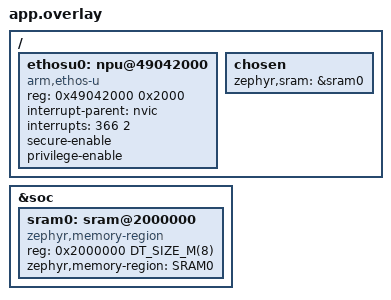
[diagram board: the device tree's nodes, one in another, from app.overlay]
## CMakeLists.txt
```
# SPDX-License-Identifier: Apache-2.0

cmake_minimum_required(VERSION 3.20.0)

# Select the AI layer's Kconfig fragments before Zephyr processes configuration.
list(APPEND EXTRA_CONF_FILE
  "${CMAKE_CURRENT_SOURCE_DIR}/ai_layer/components.conf"
  "${CMAKE_CURRENT_SOURCE_DIR}/ai_layer/operators.conf"
)

# Include the NPU node even when an older build cache has an empty overlay list.
if(NOT DTC_OVERLAY_FILE)
  set(DTC_OVERLAY_FILE "${CMAKE_CURRENT_SOURCE_DIR}/app.overlay")
endif()

find_package(Zephyr REQUIRED HINTS $ENV{ZEPHYR_BASE})
project(my_app)

add_subdirectory(ai_layer)

# Keep ExecuTorch warning suppressions local to its library.
target_compile_options(cmsis_executorch PRIVATE
  $<$<COMPILE_LANGUAGE:CXX>:-Wno-deprecated-declarations>
  $<$<COMPILE_LANG_AND_ID:CXX,GNU>:-Wno-psabi>
)

# Zephyr already provides sys/types.h for AC6; the bare-metal pack shim
# must not shadow it. Only libc++ needs compatibility adjustments here.
if(CMAKE_CXX_COMPILER_ID STREQUAL "ARMClang")
  zephyr_compile_options(-ffp-mode=full)
  # AC6 ctype macros return shifted bit masks; Zephyr's fnmatch.c uses them
  # as booleans. Put the suppression on the source so it follows -Wall;
  # a target option precedes Zephyr's flags and gets overridden by AC6.
  if(TARGET lib__posix__c_lib_ext)
    set_property(SOURCE "${ZEPHYR_BASE}/lib/posix/c_lib_ext/fnmatch.c"
      TARGET_DIRECTORY lib__posix__c_lib_ext
      APPEND PROPERTY COMPILE_OPTIONS -Wno-int-in-bool-context)
  endif()
  # Zephyr's armstdc wrappers use #include_next to chain into AC6's C headers,
  # and AC6 6.24's libc++ wrappers must precede both (notably stddef.h).
  # Explicitly add both system include paths in order: libcxx -> armstdc -> include.
  get_filename_component(_ac6_bin "${CMAKE_CXX_COMPILER}" DIRECTORY)
  get_filename_component(_ac6_include "${_ac6_bin}/../include" ABSOLUTE)
  get_filename_component(_ac6_libcxx "${_ac6_include}/libcxx" ABSOLUTE)
  if(IS_DIRECTORY "${_ac6_libcxx}")
    target_include_directories(zephyr_interface SYSTEM BEFORE INTERFACE
      "$<$<COMPILE_LANGUAGE:CXX>:${_ac6_libcxx}>")
  endif()
  if(IS_DIRECTORY "${_ac6_include}")
    target_include_directories(zephyr_interface SYSTEM INTERFACE
      "${_ac6_include}")
  endif()
  zephyr_compile_options(
    "$<$<COMPILE_LANGUAGE:CXX>:-include${CMAKE_CURRENT_SOURCE_DIR}/src/zephyr_ac6_compat.hpp>")

  # Zephyr's CMake scatter generator disables CONFIG_STATIC_INIT_GNU,
  # omitting the constructor runner and the companion destructor handler.
  if(NOT CONFIG_STATIC_INIT_GNU)
    zephyr_linker_section_configure(SECTION ctors
      INPUT ".init_array*" SORT NAME KEEP
      SYMBOLS __ac6_init_array_start __ac6_init_array_end)
    zephyr_link_libraries("--keep=*.o(.init_array*)")
    target_sources(app PRIVATE src/zephyr_ac6_init.c
      "${ZEPHYR_BASE}/lib/cpp/abi/cpp_dtors.c")
  endif()

  # Zephyr hard-codes microlib for armlink. ExecuTorch's full libc++ needs
  # the standard Arm C runtime (wide strings and AEABI assertions).
  foreach(_elf zephyr_pre0 zephyr_pre1 zephyr_final)
    if(TARGET ${_elf})
      get_target_property(_libs ${_elf} LINK_LIBRARIES)
      list(REMOVE_ITEM _libs "--library_type=microlib")
      set_property(TARGET ${_elf} PROPERTY LINK_LIBRARIES "${_libs}")
    endif()
  endforeach()
endif()

target_sources(app PRIVATE
  src/main.c
  src/arm_embedded_module.cpp
)
target_include_directories(app PRIVATE src)
if(CONFIG_EXECUTORCH_MULTIPLE_TEST)
  target_sources(app PRIVATE src/executorch_multiple_test.cpp)
else()
  target_sources(app PRIVATE src/executorch_test.cpp)
endif()

# The Corstone FVP watches UART output for EOT (0x04). Physical targets must
# not receive this control character, so enable it only from the FVP context.
if(FVP_SHUTDOWN_ON_EOT)
  target_compile_definitions(app PRIVATE FVP_SHUTDOWN_ON_EOT=1)
endif()

# Keep runtime logging consistent with the existing AI layer configuration.
zephyr_compile_definitions(ET_LOG_ENABLED=0)
```

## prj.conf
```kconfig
# The user-facing solution runs the standard single-method test.
CONFIG_EXECUTORCH_MULTIPLE_TEST=n

# Zephyr 4.5 driver configuration for the E8 NPU-HG: Ethos-U85 with 256 MACs
# per cycle. These are Zephyr Kconfig symbols, not CMSIS-Ethos-U pack settings.
CONFIG_ETHOS_U=y
CONFIG_ETHOS_U85_256=y
CONFIG_ETHOS_U_ARM=y
#CONFIG_ETHOS_U_LOG_LEVEL_NONE=y

# Ethos-U synchronization uses the kernel heap.
CONFIG_HEAP_MEM_POOL_SIZE=16384
# C++ allocations must use a heap initialized by Zephyr, including with AC6.
CONFIG_COMMON_LIBC_MALLOC=y
CONFIG_COMMON_LIBC_MALLOC_ARENA_SIZE=65536
CONFIG_LOG=y
# Keep the boot banner and kernel logs in order with the runtime's direct printf.
CONFIG_LOG_MODE_IMMEDIATE=y
CONFIG_ETHOS_U_LOG_LEVEL_INF=y
CONFIG_CACHE_MANAGEMENT=y
CONFIG_ETHOS_U_DCACHE=y

CONFIG_CPP=y
CONFIG_STD_CPP17=y

# Let Zephyr request frame-pointer omission even in unoptimized builds.
CONFIG_OVERRIDE_FRAME_POINTER_DEFAULT=y
CONFIG_OMIT_FRAME_POINTER=y

# Use the Cortex-M hardware FPU and pass floating-point arguments in FP registers.
CONFIG_FPU=y
CONFIG_FP_HARDABI=y

# Runtime loading uses C++ containers; the runner also prints float logits.
CONFIG_MAIN_STACK_SIZE=16384
CONFIG_REQUIRES_FLOAT_PRINTF=y
```

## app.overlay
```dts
/* SPDX-License-Identifier: Apache-2.0 */

/* The Ethos-U cannot DMA to the Cortex-M55 DTCM selected by the board DTS.
 * Combine SRAM0 and SRAM1 into one NPU-accessible application RAM region.
 */
/delete-node/ &sram0;
/delete-node/ &sram1;

&soc {
	sram0: sram@2000000 {
		compatible = "zephyr,memory-region", "mmio-sram";
		reg = <0x2000000 DT_SIZE_M(8)>;
		zephyr,memory-region = "SRAM0";
	};
};

/ {
	/* Alif Ensemble 2.2.1: NPU_HG_BASE and M55_HP IRQ366 (Ethos-U85). */
	ethosu0: npu@49042000 {
		compatible = "arm,ethos-u";
		reg = <0x49042000 0x2000>;
		interrupt-parent = <&nvic>;
		interrupts = <366 2>;
		secure-enable;
		privilege-enable;
		status = "okay";
	};

	chosen {
		zephyr,sram = &sram0;
	};
};
```

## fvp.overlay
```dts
/* SPDX-License-Identifier: Apache-2.0 */

/*
 * The Corstone-320 Zephyr board already declares its Ethos-U85. Keep this
 * overlay separate from app.overlay, which contains the Alif E8 NPU node.
 */

/* The SSE-320 FVP exposes UART0 in the BSP's FPGA UART window at 0x59303000.
 * The reg value is relative to the peripheral bus's 0x50000000 base.
 */
&uart0 {
	reg = <0x09303000 0x1000>;
};

/* These external UARTs use GPIO pin muxing that faults on the FVP. */
&uart3 {
	status = "disabled";
};

&uart4 {
	status = "disabled";
};

/ {
	ethosu0 {
		status = "okay";
	};
};
```

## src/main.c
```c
/*
 * Copyright (c) 2012-2014 Wind River Systems, Inc.
 *
 * SPDX-License-Identifier: Apache-2.0
 */

#include <errno.h>
#include <inttypes.h>
#include <stdio.h>

#include <zephyr/device.h>
#include <zephyr/devicetree.h>

#include <ethosu_driver.h>

#include "executorch_test.h"

#define NPU_NODE DT_NODELABEL(ethosu0)

static int finish(int result)
{
#ifdef FVP_SHUTDOWN_ON_EOT
	/* fvp_config.txt has shutdown_on_eot=1, so this ends an FVP run promptly. */
	putchar('\x04');
	fflush(stdout);
#endif
	return result;
}

int main(void)
{
	const struct device *npu = DEVICE_DT_GET(NPU_NODE);
	struct ethosu_driver_version version;
	struct ethosu_hw_info hw;
	struct ethosu_driver *drv;
	int ret = 0;

	printf("Hello World! %s\n", CONFIG_BOARD_TARGET);
	printf("Ethos-U85 (NPU-HG) driver communication check\n");
	printf("Device: %s, base: 0x%08" PRIxPTR ", IRQ: %u\n", npu->name,
	       (uintptr_t)DT_REG_ADDR(NPU_NODE), DT_IRQN(NPU_NODE));

	ethosu_get_driver_version(&version);
	printf("Driver version: %u.%u.%u\n", version.major, version.minor, version.patch);

	/* Do not reserve a driver if initialization failed: reservation would block. */
	if (!device_is_ready(npu)) {
		printf("ERROR: Ethos-U85 device initialization failed. Check the driver logs "
		       "and the board's NPU power, clock and security configuration.\n");
		return finish(-ENODEV);
	}

	drv = ethosu_reserve_driver();
	if (drv == NULL) {
		printf("ERROR: Could not reserve the Ethos-U85 driver.\n");
		return finish(-ENODEV);
	}

	/* This API reads the NPU's ID and CONFIG registers through the core driver. */
	ethosu_get_hw_info(drv, &hw);
	printf("Hardware architecture: %" PRIu32 ".%" PRIu32 ".%" PRIu32 "\n",
	       hw.version.arch_major_rev, hw.version.arch_minor_rev,
	       hw.version.arch_patch_rev);
	printf("Hardware revision: %" PRIu32 ".%" PRIu32 " (status %" PRIu32 ")\n",
	       hw.version.version_major, hw.version.version_minor, hw.version.version_status);
	printf("Product revision: %" PRIu32 "\n", hw.version.product_major);
	printf("Command stream version: %" PRIu32 "\n", hw.cfg.cmd_stream_version);
	printf("Custom DMA: %" PRIu32 "\n", hw.cfg.custom_dma);

	/* macs_per_cc is encoded as log2(MACs per cycle) by the hardware. */
	if (hw.cfg.macs_per_cc < 32U) {
		uint32_t macs = UINT32_C(1) << hw.cfg.macs_per_cc;

		printf("MACs per cycle: %" PRIu32 "\n", macs);
		if (macs != 256U) {
			printf("ERROR: Expected the E8's 256-MAC Ethos-U85 configuration.\n");
			ret = -EINVAL;
		}
	} else {
		printf("ERROR: Invalid MAC configuration: %" PRIu32 "\n", hw.cfg.macs_per_cc);
		ret = -EINVAL;
	}

	ethosu_release_driver(drv);
	if (ret == 0) {
		printf("Ethos-U85 driver communication OK (ID/configuration read; no inference).\n");
		return finish(executorch_run_test());
	}

	return finish(ret);
}
```

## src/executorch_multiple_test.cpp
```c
// Copyright 2026 Arm Limited and/or its affiliates.
// SPDX-License-Identifier: Apache-2.0

#include <array>
#include <cmath>
#include <cstdint>
#include <cstdio>
#include <cstring>
#include <limits>
#include <memory>
#include <vector>

#include <executorch/extension/data_loader/buffer_data_loader.h>
#include <executorch/runtime/core/evalue.h>
#include <executorch/runtime/core/exec_aten/exec_aten.h>
#include <executorch/runtime/core/memory_allocator.h>
#include <executorch/runtime/platform/runtime.h>

#include "arm_embedded_module.hpp"
#include "TinyCNNMultiple_pte.h"

using arm::embedded::EmbeddedModule;
using executorch::aten::DimOrderType;
using executorch::aten::ScalarType;
using executorch::aten::SizesType;
using executorch::aten::Tensor;
using executorch::aten::TensorImpl;
using executorch::extension::BufferDataLoader;
using executorch::runtime::EValue;
using executorch::runtime::MemoryAllocator;

namespace {

// Both methods stay loaded; their planned buffers have independent lifetimes.
constexpr size_t kMethodPoolSize = 256 * 1024;
constexpr size_t kTempPoolSize = 64 * 1024;

// The scratch pool must be in memory accessible to the NPU.
#ifdef APP_POOL_SECTION
#define MULTIPLE_POOL_ATTRIBUTES __attribute__((section(APP_POOL_SECTION)))
#else
#define MULTIPLE_POOL_ATTRIBUTES
#endif
alignas(64) uint8_t g_method_pool[kMethodPoolSize] MULTIPLE_POOL_ATTRIBUTES;
alignas(64) uint8_t g_temp_pool[kTempPoolSize] MULTIPLE_POOL_ATTRIBUTES;

// quantize_TinyCNNMultiple.py, seed 0, uniform input 0.25. Allow a few INT8
// rounding steps across CMSIS-NN and Ethos-U implementations.
constexpr std::array<float, 10> kReference = {
  -0.0271001998f, 0.0707616359f, 0.0542003997f, -0.0526948310f,
   0.0391447321f, 0.0271001998f, -0.0376391672f, -0.0557059646f,
  -0.1400177032f, 0.0f,
};
constexpr float kTolerance = 0.006f;

bool fail(const char *operation)
{
  printf("ExecuTorch multiple: %s failed\nTest_result: FAIL\n", operation);
  return false;
}

// Model dimensions are exported as zero-input constant methods in the .pt2.
// Reading them avoids duplicating shape constants in the application.
bool read_integer(EmbeddedModule &module, const char *name, SizesType &value)
{
  auto values = module.execute(name, std::vector<EValue>{});
  if (!values.ok() || values->size() != 1 || !values->front().isInt() ||
      values->front().toInt() <= 0 ||
      values->front().toInt() > std::numeric_limits<SizesType>::max()) {
    return fail(name);
  }
  value = static_cast<SizesType>(values->front().toInt());
  printf("%s: %ld\n", name, static_cast<long>(value));
  return true;
}

// Translate a row-major logical index into the storage layout reported by
// ExecuTorch. CPU and NPU-lowered methods may use different dimension orders.
template <class Sizes, class Strides>
size_t physical_offset(size_t logical, const Sizes &sizes, const Strides &strides)
{
  size_t offset = 0;
  for (size_t dimension = sizes.size(); dimension-- > 0;) {
    offset += (logical % sizes[dimension]) * strides[dimension];
    logical /= sizes[dimension];
  }
  return offset;
}

// Validate one named method, adapt its input layout, execute it synchronously,
// and copy the result into application-owned storage for the next stage.
template <size_t OutputRank>
bool run_method(EmbeddedModule &module, const char *method,
                const std::array<SizesType, 4> &image_shape, const std::vector<float> &input,
                const std::array<SizesType, OutputRank> &output_shape, std::vector<float> &output)
{
  auto metadata = module.method_meta(method);
  if (!metadata.ok() || metadata->num_inputs() != 1 || metadata->num_outputs() != 1) {
    return fail("method metadata");
  }
  auto tensor_metadata = metadata->input_tensor_meta(0);
  auto output_metadata = metadata->output_tensor_meta(0);
  if (!tensor_metadata.ok() || !output_metadata.ok() ||
      tensor_metadata->scalar_type() != ScalarType::Float ||
      output_metadata->scalar_type() != ScalarType::Float ||
      tensor_metadata->sizes().size() != image_shape.size() ||
      tensor_metadata->dim_order().size() != image_shape.size() ||
      output_metadata->sizes().size() != output_shape.size() ||
      tensor_metadata->nbytes() != input.size() * sizeof(float) ||
      output_metadata->nbytes() != output.size() * sizeof(float)) {
    return fail("tensor metadata");
  }
  auto sizes = image_shape;
  std::array<DimOrderType, 4> order{};
  std::array<size_t, 4> strides{};
  for (size_t i = 0; i < image_shape.size(); ++i) {
    if (tensor_metadata->sizes()[i] != image_shape[i]) {
      return fail("input shape");
    }
    order[i] = tensor_metadata->dim_order()[i];
  }
  for (size_t i = 0; i < output_shape.size(); ++i) {
    if (output_metadata->sizes()[i] != output_shape[i]) {
      return fail("output shape");
    }
  }
  size_t stride = 1;
  for (size_t i = image_shape.size(); i-- > 0;) {
    strides[order[i]] = stride;
    stride *= image_shape[order[i]];
  }
  // Pipeline buffers use logical contiguous order. Import the layout expected
  // by the method, which can differ between CPU and NPU lowering.
  std::vector<float> physical_input(input.size());
  for (size_t i = 0; i < input.size(); ++i) {
    physical_input[physical_offset(i, image_shape, strides)] = input[i];
  }
  TensorImpl implementation(ScalarType::Float, sizes.size(), sizes.data(),
                            physical_input.data(), order.data());
  auto results = module.execute(method, EValue(Tensor(&implementation)));
  if (!results.ok() || results->size() != 1 || !results->front().isTensor()) {
    return fail(method);
  }
  const auto tensor = results->front().toTensor();
  if (tensor.scalar_type() != ScalarType::Float ||
      static_cast<size_t>(tensor.numel()) != output.size()) {
    return fail("output tensor");
  }
  // Copy before executing another method: output storage belongs to the method.
  for (size_t i = 0; i < output.size(); ++i) {
    output[i] = tensor.const_data_ptr<float>()[physical_offset(i, output_shape, tensor.strides())];
  }
  return true;
}

} // namespace

extern "C" int executorch_run_test(void)
{
  executorch::runtime::runtime_init();
  printf("ExecuTorch filter/classify application: %lu byte program\n", TinyCNNMultiple_pte_size);
  // NOLOAD scratch sections are not zeroed at boot.
  std::memset(g_temp_pool, 0, sizeof(g_temp_pool));
  // The firmware does not contain the source .pt2 file. Model conversion
  // lowers it to .pte and emits this const byte array, normally linked in
  // read-only flash. The loader reads the program directly from that array.
  EmbeddedModule module(
      TinyCNNMultiple_pte, TinyCNNMultiple_pte_size,
      std::make_unique<BufferDataLoader>(TinyCNNMultiple_pte, TinyCNNMultiple_pte_size),
      std::make_unique<MemoryAllocator>(kMethodPoolSize, g_method_pool),
      std::make_unique<MemoryAllocator>(kTempPoolSize, g_temp_pool));
  if (module.load() != executorch::runtime::Error::Ok) {
    fail("load");
    return 1;
  }

  // Execute the four constant methods sequentially. The || chain stops at the
  // first missing or invalid value; it does not run these calls in parallel.
  SizesType image_width, image_height, input_channels, num_classes;
  if (!read_integer(module, "IMAGE_WIDTH", image_width) ||
      !read_integer(module, "IMAGE_HEIGHT", image_height) ||
      !read_integer(module, "INPUT_CHANNELS", input_channels) ||
      !read_integer(module, "NUM_CLASSES", num_classes)) {
    return 1;
  }
  // One NHWC image for inference; filtering preserves its dimensions.
  const std::array<SizesType, 4> image_shape = {1, image_height, image_width, input_channels};
  const std::array<SizesType, 2> output_shape = {1, num_classes};
  size_t image_elements = 1;
  for (auto dimension : image_shape) {
    if (static_cast<size_t>(dimension) >
        std::numeric_limits<size_t>::max() / sizeof(float) / image_elements) {
      fail("image size");
      return 1;
    }
    image_elements *= dimension;
  }
  if (static_cast<size_t>(num_classes) != kReference.size()) {
    fail("reference size");
    return 1;
  }

  // Run the two data-processing methods as a pipeline. filter must finish and
  // populate filtered_image before classify can consume it.
  std::vector<float> image(image_elements, 0.25f);
  std::vector<float> filtered_image(image_elements);
  std::vector<float> logits(num_classes);
  if (!run_method(module, "filter", image_shape, image, image_shape, filtered_image)) {
    return 1;
  }
  if (!run_method(module, "classify", image_shape, filtered_image, output_shape, logits)) {
    return 1;
  }

  // Compare every classifier output with the reference generated by the
  // quantization script. Non-finite values always fail the test.
  int result = 0;
  printf("Output:");
  for (size_t i = 0; i < logits.size(); ++i) {
    printf(" %.6f", static_cast<double>(logits[i]));
    if (!std::isfinite(logits[i]) || std::fabs(logits[i] - kReference[i]) > kTolerance) {
      result = 1;
    }
  }
  printf("\nReference comparison (absolute tolerance %.3f): %s\n",
         static_cast<double>(kTolerance), result ? "FAIL" : "PASS");
  printf("Test_result: %s\n", result ? "FAIL" : "PASS");
  fflush(stdout);
  return result;
}
```

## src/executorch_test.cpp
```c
// Copyright 2026 Arm Limited and/or its affiliates.
// SPDX-License-Identifier: Apache-2.0
// Adapted from CMSIS-Executorch/src/app_main.cpp for the Zephyr application.

#include <array>
#include <cstdint>
#include <cstdio>
#include <cstring>
#include <memory>

#include <executorch/extension/data_loader/buffer_data_loader.h>
#include <executorch/runtime/core/evalue.h>
#include <executorch/runtime/core/exec_aten/exec_aten.h>
#include <executorch/runtime/core/memory_allocator.h>
#include <executorch/runtime/platform/runtime.h>

#include "arm_embedded_module.hpp"
#include "executorch_test.h"
#include "TinyCNN_pte.h"

using arm::embedded::EmbeddedModule;
using executorch::aten::DimOrderType;
using executorch::aten::ScalarType;
using executorch::aten::SizesType;
using executorch::aten::Tensor;
using executorch::aten::TensorImpl;
using executorch::extension::BufferDataLoader;
using executorch::runtime::EValue;
using executorch::runtime::MemoryAllocator;

namespace {

// TinyCNN needs much less space than the original example's two 4 MiB pools.
constexpr size_t kMethodPoolSize = 128 * 1024;
constexpr size_t kTempPoolSize = 64 * 1024;

alignas(64) uint8_t g_method_pool[kMethodPoolSize];
// The NPU uses scratch directly. The default .bss is writable system SRAM on
// both supplied targets and is accessible by the Ethos-U.
alignas(64) uint8_t g_temp_pool[kTempPoolSize];

} // namespace

extern "C" int executorch_run_test(void)
{
  executorch::runtime::runtime_init();
  printf("ExecuTorch Ethos-U85-256 application: %lu byte program\n", TinyCNN_pte_size);

  // Devicetree memory-region sections are NOLOAD and are not zeroed at boot.
  std::memset(g_temp_pool, 0, sizeof(g_temp_pool));

  EmbeddedModule module(
      TinyCNN_pte, TinyCNN_pte_size,
      std::make_unique<BufferDataLoader>(TinyCNN_pte, TinyCNN_pte_size),
      std::make_unique<MemoryAllocator>(kMethodPoolSize, g_method_pool),
      std::make_unique<MemoryAllocator>(kTempPoolSize, g_temp_pool));

  // Same deterministic image values as the CMSIS pack example. The supplied
  // U85 PTE exposes NCHW, whereas the original runner hard-codes NHWC.
  alignas(16) static float input_data[16 * 16 * 3];
  auto method_meta = module.method_meta("forward");
  if (!method_meta.ok()) {
    printf("Could not read forward metadata (err=%u)\nTest_result: FAIL\n",
           static_cast<unsigned>(method_meta.error()));
    return 1;
  }
  if (method_meta->num_inputs() != 1) {
    printf("forward expected one input\nTest_result: FAIL\n");
    return 1;
  }
  auto input_meta = method_meta->input_tensor_meta(0);
  if (!input_meta.ok() || input_meta->scalar_type() != ScalarType::Float ||
      input_meta->sizes().size() != 4 || input_meta->dim_order().size() != 4 ||
      input_meta->nbytes() != sizeof(input_data)) {
    printf("forward expected a rank-four RGB image with 768 floats\n"
           "Test_result: FAIL\n");
    return 1;
  }

  for (size_t i = 0; i < sizeof(input_data) / sizeof(input_data[0]); ++i) {
    input_data[i] = static_cast<float>(i % 32) / 32.0f - 0.5f;
  }
  std::array<SizesType, 4> sizes;
  std::array<DimOrderType, 4> dim_order;
  for (size_t i = 0; i < sizes.size(); ++i) {
    sizes[i] = input_meta->sizes()[i];
    dim_order[i] = input_meta->dim_order()[i];
  }
  printf("Input shape: [%ld, %ld, %ld, %ld]\n", static_cast<long>(sizes[0]),
         static_cast<long>(sizes[1]), static_cast<long>(sizes[2]),
         static_cast<long>(sizes[3]));
  TensorImpl input_impl(ScalarType::Float, sizes.size(), sizes.data(), input_data,
                        dim_order.data());
  Tensor input(&input_impl);

  auto outputs = module.forward(input);
  if (!outputs.ok()) {
    printf("forward failed (err=%u)\nTest_result: FAIL\n",
           static_cast<unsigned>(outputs.error()));
    return 1;
  }
  if (outputs->size() != 1 || !outputs->front().isTensor()) {
    printf("forward expected one output tensor\nTest_result: FAIL\n");
    return 1;
  }

  const EValue& out = outputs->front();
  Tensor tensor = out.toTensor();
  const auto num_output_elements = tensor.numel();
  if (tensor.scalar_type() != ScalarType::Float || num_output_elements != 10) {
    printf("forward expected ten float logits\nTest_result: FAIL\n");
    return 1;
  }

  // The signed element count is positive after the ten-logit check above.
  const auto output_count = static_cast<size_t>(num_output_elements);
  printf("Output: %zu element(s):", output_count);
  const float* data = tensor.const_data_ptr<float>();
  for (size_t i = 0; i < output_count; ++i) {
    printf(" %.4f", static_cast<double>(data[i]));
  }
  printf("\nTest_result: PASS\n");
  fflush(stdout);
  return 0;
}
```
